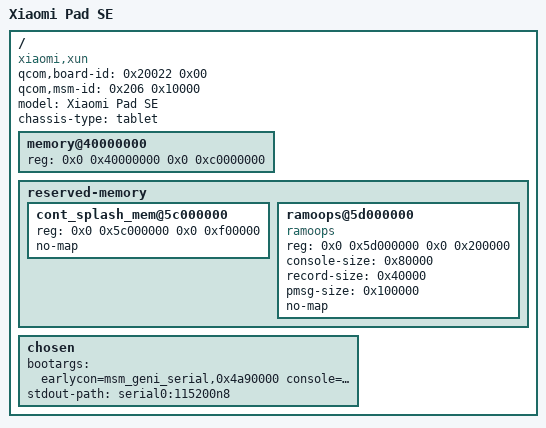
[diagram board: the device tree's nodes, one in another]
// SPDX-License-Identifier: BSD-3-Clause
/dts-v1/;

#include "sm6225.dtsi"
#include <dt-bindings/gpio/gpio.h>
#include <dt-bindings/input/input.h>
#include <dt-bindings/input/gpio-keys.h>

/ {
	qcom,board-id = <0x20022 0x00>;
	qcom,msm-id = <0x206 0x10000>;

	model = "Xiaomi Pad SE";
	compatible = "xiaomi,xun", "qcom,sm6225", "qcom,khaje";
	chassis-type = "tablet";

	/*
	 * Memory map from stock /proc/device-tree (8 GB unit).
	 * Keep conservative until earlycon confirms.
	 */
	memory@40000000 {
		device_type = "memory";
		reg = <0x0 0x40000000 0x0 0xc0000000>;
	};

	reserved-memory {
		#address-cells = <2>;
		#size-cells = <2>;
		ranges;

		/* Splash / logo buffer seen on stock (optional reserve) */
		cont_splash_mem@5c000000 {
			reg = <0x0 0x5c000000 0x0 0xf00000>;
			no-map;
		};

		/*
		 * ramoops: pick a region after splash. If empty after a hang,
		 * try extracting stock ramoops address from /proc/device-tree.
		 */
		ramoops@5d000000 {
			compatible = "ramoops";
			reg = <0x0 0x5d000000 0x0 0x200000>;
			console-size = <0x80000>;
			record-size = <0x40000>;
			pmsg-size = <0x100000>;
			no-map;
		};
	};

	chosen {
		/*
		 * earlycon on QUPv3 UART SE4 @ 0x4a90000 (stock debug UART).
		 * No simple-framebuffer until DRM works — logo hang is expected
		 * without display driver; use pstore after reboot to stock.
		 */
		bootargs = "earlycon=msm_geni_serial,0x4a90000 console=ttyMSM0,115200n8 console=tty0 clk_ignore_unused pd_ignore_unused loglevel=8 ignore_loglevel PMOS_NOSPLASH";
		stdout-path = "serial0:115200n8";
	};
};
